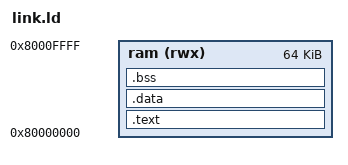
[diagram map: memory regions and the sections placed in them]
OUTPUT_ARCH(riscv)
ENTRY(_start)
MEMORY { ram (rwx) : ORIGIN = 0x80000000, LENGTH = 64K }
SECTIONS {
  .text : { *(.text.start) *(.text*) *(.rodata*) *(.srodata*) } > ram
  .data : { *(.data*) *(.sdata*) } > ram
  .bss  : { *(.bss*) *(.sbss*) *(COMMON) } > ram
  _stack_top = ORIGIN(ram) + LENGTH(ram);
}
